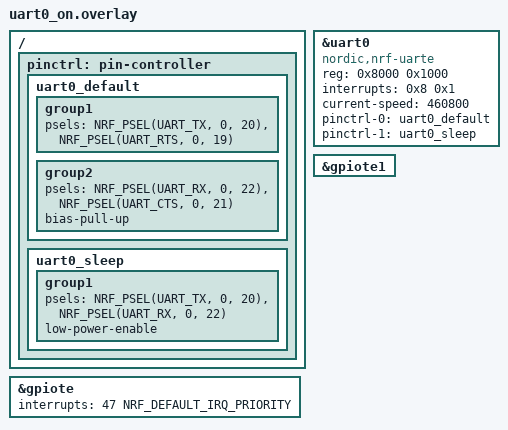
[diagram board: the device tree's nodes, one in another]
/ {
	pinctrl: pin-controller {
		uart0_default: uart0_default {
			group1 {
				psels = <NRF_PSEL(UART_TX, 0, 20)>,
						<NRF_PSEL(UART_RTS, 0, 19)>;
			};
			group2 {
				psels = <NRF_PSEL(UART_RX, 0, 22)>,
						<NRF_PSEL(UART_CTS, 0, 21)>;
				bias-pull-up;
			};
		};

		uart0_sleep: uart0_sleep {
			group1 {
				psels = <NRF_PSEL(UART_TX, 0, 20)>,
						<NRF_PSEL(UART_RX, 0, 22)>;
				low-power-enable;
			};
		};
	};
};

&uart0 {
	compatible = "nordic,nrf-uarte";
	reg = < 0x8000 0x1000 >;
	interrupts = < 0x8 0x1 >;
	status = "okay";
	current-speed = <460800>;
	pinctrl-0 = <&uart0_default>;
	pinctrl-1 = <&uart0_sleep>;
	pinctrl-names = "default", "sleep";
};

&gpiote1 {
	status = "okay";
};

&gpiote {
	interrupts = <47 NRF_DEFAULT_IRQ_PRIORITY>;
};
